# DA14586 register map
Vendor: Dialog; Series: DA1458x; File version: 1.2
CPU: CM0 r1p0, little endian, MPU, FPU, 3 interrupt priority bits
Registers are 16-bit, read-write, reset 0x0 unless marked. A register's access mark holds for its fields unless they carry their own. Offsets are from the block's base; [hi:lo] are bit positions; {n}, {i} and the like mark numbered series.

## SCB — Cortex M0 SCB registers
Base 0xE000ED00
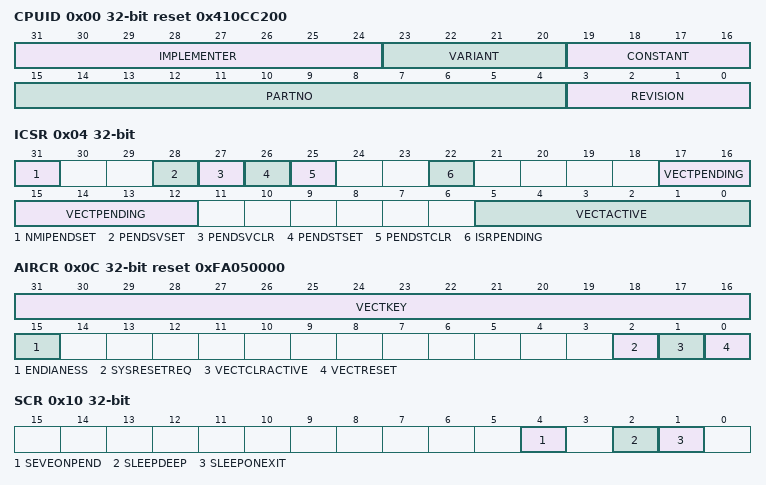
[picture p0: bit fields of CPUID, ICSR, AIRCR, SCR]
0x00 CPUID 32-bit reset 0x410CC200 — CPUID base register
  [31:24] IMPLEMENTER ro — IMPLEMENTER[7:0] bits (Implementer code)
  [23:20] VARIANT ro — VARIANT[3:0] bits (Variant number)
  [19:16] CONSTANT ro — CONSTANT[3:0] bits (Reads as 0xF)
  [15:4] PARTNO ro — PARTNO[11:0] bits (Part number of the processor core)
  [3:0] REVISION ro — REVISION[3:0] bits (Revision number)
0x04 ICSR 32-bit — Interrupt control and state register
  [31] NMIPENDSET — NMI set-pending bit
  [28] PENDSVSET — PendSV set-pending bit
  [27] PENDSVCLR — PendSV clear-pending bit
  [26] PENDSTSET — SysTick exception set-pending bit
  [25] PENDSTCLR — SysTick exception clear-pending bit
  [22] ISRPENDING — Interrupt pending flag, excluding NMI and Faults
  [17:12] VECTPENDING — VECTPENDING[5:0] bits (Pending vector)
  [5:0] VECTACTIVE — VECTACTIVE[5:0] bits (Active vector)
0x0C AIRCR 32-bit ro reset 0xFA050000 — Application interrupt and reset control register
  [31:16] VECTKEY — VECTKEY[15:0] bits (Register key)
  [15] ENDIANESS — Data endianness bit
  [2] SYSRESETREQ — System reset request
  [1] VECTCLRACTIVE — Reserved for Debug use
  [0] VECTRESET — Reserved for Debug use
0x10 SCR 32-bit — System control register
  [4] SEVEONPEND — Send event on pending bit
  [2] SLEEPDEEP — Controls whether the processor uses sleep or deep sleep
  [1] SLEEPONEXIT — Configures sleep-on-exit when returning from Handler mode to Thread mode
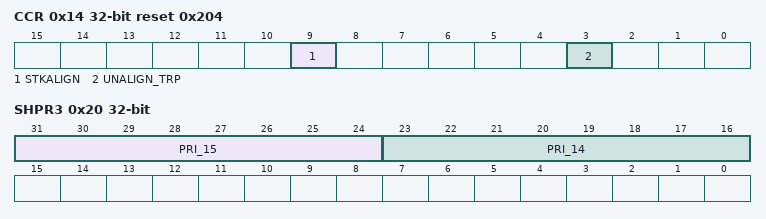
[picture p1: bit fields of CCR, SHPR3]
0x14 CCR 32-bit reset 0x204 — Configuration and control register
  [9] STKALIGN — Configures stack alignment on exception entry
  [3] UNALIGN_TRP — Enables unaligned access traps
0x1C SHPR2 32-bit — System handler priority register 2
  [31:24] PRI_11 — PRI_11[7:0] bits (Priority of system handler 11, SVCall)
0x20 SHPR3 32-bit — System handler priority register 3
  [31:24] PRI_15 — PRI_15[7:0] bits (Priority of system handler 15, SysTick exception)
  [23:16] PRI_14 — PRI_14[7:0] bits (Priority of system handler 14, PendSV)

## SysTick — Cortex M0 SysTick registers
Base 0xE000E010
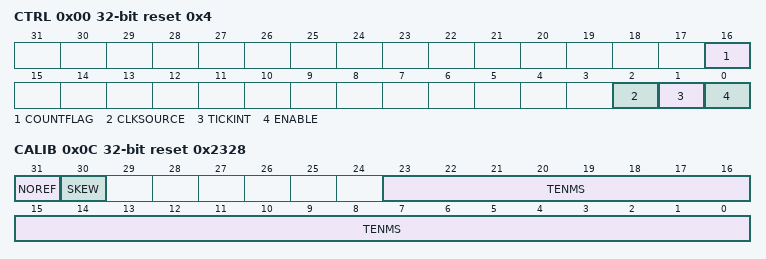
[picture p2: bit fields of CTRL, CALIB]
0x00 CTRL 32-bit reset 0x4 — SysTick Control and Status register
  [16] COUNTFLAG — Timer counted to 0 since last time this was read
  [2] CLKSOURCE — Clock source selection
  [1] TICKINT — SysTick exception request enable
  [0] ENABLE — SysTick Counter enable
0x04 LOAD 32-bit — SysTick Reload value register
  [23:0] RELOAD — RELOAD[23:0] bits (Reload value)
0x08 VAL 32-bit — SysTick Current value register
  [23:0] CURRENT — CURRENT[23:0] bits (Current counter value)
0x0C CALIB 32-bit ro reset 0x2328 — SysTick Calibration value register
  [31] NOREF — Indicates that a separate reference clock is provided
  [30] SKEW — Indicates whether the TENMS value is exact
  [23:0] TENMS — TENMS[23:0] bits (Calibration value)

## ambacore580_patch_gr00 — ambacore580_patch_gr00 registers
Base 0x40008400
0x00 PATCH_VALID_REG 32-bit — Validity Control Register
  [7:0] PATCH_VALID — Indicates which patch entry is valid. For example, when bit 0 is high it indicates that entry 0 is valid, i.e. the values of PATCH_ADDR0_REG / PATCH_DATA0_REG, are effective.
0x04 PATCH_VALID_SET_REG 32-bit — Validity Set Control Register
  [7:0] PATCH_VALID_SET — Writing a bit with 1 will set the corresponding bit of PATCH_VALID_REG to 1. Writing a bit with 0 is ignored. Read always as 0.
0x08 PATCH_VALID_RESET_REG 32-bit — Validity Reset Control Register
  [7:0] PATCH_VALID_RESET — Writing a bit with 1 will clear the corresponding bit of PATCH_VALID_REG to 0. Writing a bit with zero is ignored. Read always as 0.
{0x10+8i} PATCH_ADDR{i}_REG 32-bit (reset mask 0x7FFFFFFF) (i=0..7) — Patch entry {i}: Address field
  [31:0] PATCH_ADDR — This is the value which will be compared to the address on the AHB. If a match occurs, the data bus willl be filled with the value in the respective PATCH_DATAx_REG. Bits [1:0] are read-only and always read as '0'. Never use the base address 0x0 for values in PATCH_ADDRx_REG because HW Patch block is located after the Address Remapping block.
{0x14+8i} PATCH_DATA{i}_REG 32-bit (reset mask 0x7FFFFFFF) (i=0..7) — Patch entry {i}: Data field
  [31:0] PATCH_DATA — This is the value which will be injected into the data bus if there is a match on the comparison of the address with the respective PATCH_ADDRx_REG
